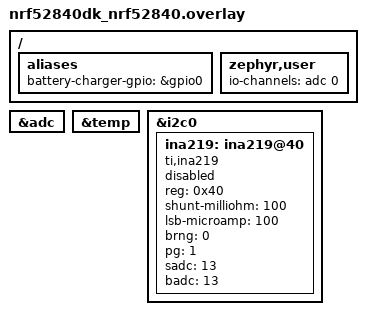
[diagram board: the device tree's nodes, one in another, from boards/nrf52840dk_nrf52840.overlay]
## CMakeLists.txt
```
cmake_minimum_required(VERSION 3.20.0)
find_package(Zephyr REQUIRED HINTS $ENV{ZEPHYR_BASE})
project(battery_sdk_app)

target_sources(app PRIVATE
    src/main.c
    ../src/core/battery_sdk.c
    ../src/core_modules/battery_adc.c
    ../src/core_modules/battery_power_manager.c
    ../src/core_modules/battery_temperature.c
    ../src/core_modules/battery_voltage.c
    ../src/intelligence/battery_soc_estimator.c
    ../src/intelligence/battery_soc_lut.c
    $<$<BOOL:${CONFIG_BATTERY_SOC_TEMP_COMP}>:../src/intelligence/battery_soc_temp_comp.c>
    ../src/telemetry/battery_telemetry.c
    $<$<BOOL:${CONFIG_BATTERY_TRANSPORT}>:../src/transport/battery_transport.c>
    $<$<BOOL:${CONFIG_BATTERY_TRANSPORT}>:../src/transport/battery_serialize.c>
    $<$<BOOL:${CONFIG_BATTERY_TRANSPORT_BLE}>:../src/transport/ble/battery_transport_ble_zephyr.c>
    ../src/hal/battery_hal_zephyr.c
    ../src/hal/battery_hal_adc_zephyr.c
    $<$<BOOL:${CONFIG_BATTERY_CHARGER_TP4056}>:../src/hal/battery_hal_charger_tp4056_zephyr.c>
    ../src/intelligence/battery_cycle_counter.c
)

# NVS HAL: real Zephyr NVS or stub
if(CONFIG_BATTERY_CYCLE_COUNTER OR CONFIG_BATTERY_SOC_SOH)
    target_sources(app PRIVATE ../src/hal/battery_hal_nvs_zephyr.c)
else()
    target_sources(app PRIVATE ../src/hal/battery_hal_nvs_stub.c)
endif()

# Current sensing HAL: Zephyr sensor API or stub
if(CONFIG_BATTERY_CURRENT_SENSE)
    target_sources(app PRIVATE ../src/hal/battery_hal_current_zephyr.c)
else()
    target_sources(app PRIVATE ../src/hal/battery_hal_current_stub.c)
endif()

# Coulomb counter
if(CONFIG_BATTERY_SOC_COULOMB)
    target_sources(app PRIVATE ../src/intelligence/battery_coulomb.c)
endif()

# SoC fusion (voltage + coulomb blending)
if(CONFIG_BATTERY_SOC_FUSION)
    target_sources(app PRIVATE ../src/intelligence/battery_soc_fusion.c)
endif()

# Runtime-to-empty estimator (time remaining)
if(CONFIG_BATTERY_RUNTIME_TO_EMPTY)
    target_sources(app PRIVATE ../src/intelligence/battery_runtime.c)
endif()

# State of Health (capacity-fade learning)
if(CONFIG_BATTERY_SOC_SOH)
    target_sources(app PRIVATE ../src/intelligence/battery_soh.c)
endif()

# Swap-aware SoH auto-reset (power-off battery swap detection)
if(CONFIG_BATTERY_SWAP_DETECT)
    target_sources(app PRIVATE ../src/intelligence/battery_swap.c)
endif()

# Zephyr fuel_gauge driver API (read-only) + its conversion helpers
if(CONFIG_BATTERY_FUEL_GAUGE_API)
    target_sources(app PRIVATE
        ../src/fuel_gauge/battery_fuel_gauge_zephyr.c
        ../src/core_modules/battery_fuel_gauge_convert.c
    )
endif()

# Voltage filter: moving-average (default) or median
if(CONFIG_BATTERY_VOLTAGE_FILTER_MEDIAN)
    target_sources(app PRIVATE ../src/core_modules/battery_voltage_filter_median.c)
else()
    target_sources(app PRIVATE ../src/core_modules/battery_voltage_filter.c)
endif()

# Temperature HAL: NTC thermistor or internal die sensor
if(CONFIG_BATTERY_TEMP_NTC)
    target_sources(app PRIVATE
        ../src/hal/battery_hal_temp_ntc_zephyr.c
        ../src/intelligence/battery_ntc_lut.c
    )
else()
    target_sources(app PRIVATE
        ../src/hal/battery_hal_temp_zephyr.c
    )
endif()

target_include_directories(app PRIVATE
    ${CMAKE_CURRENT_SOURCE_DIR}/../include
    ${CMAKE_CURRENT_SOURCE_DIR}/../src
    ${CMAKE_CURRENT_SOURCE_DIR}/../src/core
    ${CMAKE_CURRENT_SOURCE_DIR}/../src/core_modules
    ${CMAKE_CURRENT_SOURCE_DIR}/../src/hal
    ${CMAKE_CURRENT_SOURCE_DIR}/../src/intelligence
    ${CMAKE_CURRENT_SOURCE_DIR}/../src/telemetry
    ${CMAKE_CURRENT_SOURCE_DIR}/../src/transport
)
```

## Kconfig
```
# Battery SDK sample-application configuration.
#
# All CONFIG_BATTERY_* option definitions live in app/Kconfig.battery, which
# is ALSO sourced by the Zephyr-module Kconfig (Kconfig.ibattery) — single
# source of truth, so the app and module config trees cannot drift.

rsource "Kconfig.battery"

source "Kconfig.zephyr"
```

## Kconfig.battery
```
# iBattery SDK — battery option definitions (single source of truth)
#
# Sourced by BOTH the sample-app Kconfig (app/Kconfig) and the Zephyr-module
# Kconfig (Kconfig.ibattery), so the app and module config trees cannot drift.
# Define every CONFIG_BATTERY_* option here — nowhere else.

menu "Battery SDK"

choice BATTERY_CHEMISTRY
    prompt "Battery chemistry"
    default BATTERY_CHEMISTRY_CR2032

config BATTERY_CHEMISTRY_CR2032
    bool "CR2032 primary lithium coin cell (3.0 V nominal)"
    help
      CR2032 primary (non-rechargeable) lithium coin cell.
      Nominal voltage 3.0 V, cutoff ~2.0 V.

config BATTERY_CHEMISTRY_LIPO
    bool "LiPo single-cell (3.7 V nominal)"
    help
      Lithium-polymer rechargeable cell.  Nominal voltage 3.7 V,
      full charge 4.2 V, cutoff 3.0 V.

endchoice

choice BATTERY_TEMP_SOURCE
    prompt "Temperature sensor source"
    default BATTERY_TEMP_NTC

config BATTERY_TEMP_NTC
    bool "External NTC thermistor (10K B3950)"
    help
      Use an external NTC thermistor in a voltage divider on an ADC
      channel for temperature measurement. The exact pin is defined in
      the board's devicetree overlay. Requires a 10K pull-up resistor
      to VDD and a 10K NTC (B=3950) to GND.

config BATTERY_TEMP_DIE
    bool "Internal die temperature sensor"
    select SENSOR
    select TEMP_NRF5 if SOC_SERIES_NRF52X
    select ESP32_TEMP if SOC_SERIES_ESP32C3
    help
      Use the SoC internal die temperature sensor via the Zephyr
      sensor API. No external components needed, but measures chip
      temperature rather than ambient/battery temperature.

endchoice

choice BATTERY_VOLTAGE_FILTER_TYPE
    prompt "Voltage filter algorithm"
    default BATTERY_VOLTAGE_FILTER_MEAN

config BATTERY_VOLTAGE_FILTER_MEAN
    bool "Moving average (legacy)"
    help
      Simple moving average over the configured window. Smooths
      gradual changes but lets short voltage sags through.

config BATTERY_VOLTAGE_FILTER_MEDIAN
    bool "Median (rejects load-induced sags)"
    help
      Sorted median over the configured window. Single-sample
      outliers (e.g. BLE TX voltage sag) are completely rejected.

endchoice

config BATTERY_TRANSPORT
    bool "Enable telemetry transport"
    default n
    help
      Enable the transport abstraction layer for sending telemetry
      packets off-device (BLE, serial, etc.).

if BATTERY_TRANSPORT

choice BATTERY_TRANSPORT_BACKEND
    prompt "Transport backend"
    default BATTERY_TRANSPORT_BLE

config BATTERY_TRANSPORT_BLE
    bool "Bluetooth Low Energy (BLE)"
    select BT
    select BT_PERIPHERAL
    help
      Send telemetry via BLE GATT notifications using a custom service.
      Requires a BLE-capable SoC or external BLE shield (e.g.
      X-NUCLEO-IDB05A2 on STM32 Nucleo boards).

endchoice

endif # BATTERY_TRANSPORT

config BATTERY_SOC_TEMP_COMP
    bool "Temperature-compensated SoC estimation"
    default y if BATTERY_TEMP_NTC && BATTERY_CHEMISTRY_LIPO
    depends on BATTERY_CHEMISTRY_LIPO
    help
      Enable temperature-compensated SoC estimation by blending between
      cold (0 deg C), room (25 deg C), and hot (45 deg C) LiPo LUT tables.
      Requires LiPo chemistry and a working temperature sensor.  Falls back
      to room-temperature LUT if the temperature read fails at runtime.

config BATTERY_CYCLE_COUNTER
    bool "Charge cycle counter with flash persistence"
    default y if BATTERY_CHARGER_TP4056
    select NVS
    select FLASH
    select FLASH_MAP
    help
      Count CHARGING to CHARGED transitions and persist the count
      to flash via Zephyr NVS.  Requires a charger driver for meaningful
      state transitions.

config BATTERY_CURRENT_SENSE
    bool "Enable current sensing (INA219)"
    default n
    select SENSOR
    select I2C
    help
      Enable current measurement via an INA219 I2C sensor.
      Required for coulomb counting SoC estimation.
      The INA219 must be defined in the board's devicetree overlay.

config BATTERY_VOLTAGE_ADC
    bool
    default y
    select ADC
    help
      The Zephyr voltage HAL (src/hal/battery_hal_adc_zephyr.c) is compiled
      unconditionally and hard-depends on the ADC subsystem (DEVICE_DT_GET of
      the ADC node + adc_raw_to_millivolts/adc_gain_invert).  Pull ADC in here
      so the SDK declares its own dependency — mirroring how BATTERY_TEMP_DIE
      selects SENSOR.  Without this, a module consumer that does not set
      CONFIG_ADC itself fails to link (the sample app sets CONFIG_ADC=y in its
      prj.conf, which masked this on the app-path build).  Hidden / always-on.

config BATTERY_VOLTAGE_EXTERNAL_ADC
    bool "Read battery voltage from an external ADC pin + resistor divider"
    default n
    help
      Read battery voltage from an external resistor divider on an ADC pin
      instead of the internal VDD path (STM32 VREFINT).  This lets a real
      cell or a bench source-measure unit (e.g. Nordic PPK2) drive the sensed
      voltage independently of the MCU supply, so a full->empty excursion can
      be exercised without browning out the board.  STM32L4 reads Arduino A2 /
      PA4 (ADC1_IN9); the board overlay must enable that channel.  ESP32-C3
      always uses an external divider regardless of this option.

config BATTERY_VOLTAGE_DIVIDER_RATIO
    int "Battery voltage divider ratio (R1+R2)/R2"
    default 2
    range 1 16
    depends on BATTERY_VOLTAGE_EXTERNAL_ADC
    help
      Ratio applied to the ADC pin voltage to reconstruct battery voltage.
      For R1 = R2 (e.g. 100k/100k) the ratio is 2 (V_batt = V_pin * 2).

config BATTERY_SOC_COULOMB
    bool "Coulomb counting SoC estimation"
    default y if BATTERY_CURRENT_SENSE
    depends on BATTERY_CURRENT_SENSE
    help
      Use coulomb counting (current integration) as the primary
      SoC estimation method, with voltage-LUT anchoring at
      full-charge and cutoff endpoints. Falls back to voltage-LUT
      if current sensor is unavailable at runtime.

config BATTERY_CAPACITY_MAH
    int "Battery capacity in mAh"
    range 1 65535
    default 220 if BATTERY_CHEMISTRY_CR2032
    default 1000 if BATTERY_CHEMISTRY_LIPO
    depends on BATTERY_SOC_COULOMB || BATTERY_FUEL_GAUGE_API
    help
      Nominal battery capacity in milliamp-hours. Used by the
      coulomb counting estimator to convert accumulated charge
      to SoC percentage.

config BATTERY_SOC_SLEW_LIMIT
    bool "Limit SoC change rate (smooths reported value)"
    default y
    help
      Caps the SoC change rate to a configurable maximum percent per
      minute. Filters transient SoC swings from voltage sag or LUT
      plateau cliffs. Bypassed on first sample after init.

config BATTERY_SOC_SLEW_RATE_PCT_PER_MIN
    int "Max SoC change per minute (percent)"
    default 5
    range 1 100
    depends on BATTERY_SOC_SLEW_LIMIT
    help
      Maximum allowed SoC change per minute.

config BATTERY_SOC_FUSION
    bool "Voltage + coulomb signal fusion"
    default n
    depends on BATTERY_SOC_COULOMB
    help
      Continuously fuses voltage-LUT SoC with coulomb-counter SoC to
      correct mid-discharge drift in the coulomb integrator. Trust
      shifts toward voltage when the battery is at rest (current below
      threshold) and toward coulomb under load (voltage sag is real).

      Composes with the endpoint anchor calibration (which still fires
      at the discharge curve's endpoints) and the SoC slew limiter (which
      still applies after fusion).

      Defaults to off. Enable per build to opt in.

if BATTERY_SOC_FUSION

config BATTERY_SOC_FUSION_ALPHA_REST_X1000
    int "Fusion alpha (x1000) when battery is at rest"
    default 50 if !BATTERY_CHEMISTRY_LIPO
    default 30 if BATTERY_CHEMISTRY_LIPO
    range 0 1000
    help
      Per-sample pull toward voltage-LUT SoC when the current magnitude
      is below the rest/load threshold (I_THRESH_X100).
      Larger = faster drift correction. Default 5.0% per sample (CR2032)
      gives ~95% convergence in ~60 samples at 2s intervals.
      LiPo default is 3.0% (LUT is flatter in the middle plateau, so
      voltage is less informative even at rest).

config BATTERY_SOC_FUSION_ALPHA_LOAD_X1000
    int "Fusion alpha (x1000) under load"
    default 5
    range 0 1000
    help
      Per-sample pull toward voltage-LUT SoC when the current magnitude
      is at or above the rest/load threshold (I_THRESH_X100).
      Should be small -- voltage is unreliable under load (IR drop).
      Default 0.5% per sample, both chemistries.

config BATTERY_SOC_FUSION_I_THRESH_X100
    int "Current threshold (x100 mA) classifying rest vs load"
    default 200 if !BATTERY_CHEMISTRY_LIPO
    default 5000 if BATTERY_CHEMISTRY_LIPO
    # Upper bound 500000 = 5000.00 mA (5 A) — generous even for a 500 mAh
    # LiPo (10C); defaults are 2 mA (CR2032) / 50 mA (LiPo).
    range 0 500000
    help
      Below this current magnitude, fusion uses ALPHA_REST.
      At or above it, uses ALPHA_LOAD. Units are x100 mA
      (e.g. 200 = 2.00 mA).

endif # BATTERY_SOC_FUSION

config BATTERY_SOC_SOH
    bool "State-of-Health (capacity-fade learning)"
    default n
    depends on BATTERY_SOC_COULOMB
    select NVS
    select FLASH
    select FLASH_MAP
    help
      Learns the battery's true usable capacity from full->empty discharge
      excursions and exposes State of Health (SoH = learned / rated). The
      coulomb integral between a full and an empty anchor is the actual
      delivered charge; an aged cell delivers less, which shows up as SoH
      below 100%. Learned capacity persists to flash (NVS) and is restored on
      boot behind a rated-capacity guard. Opt-in; default off.

if BATTERY_SOC_SOH

config BATTERY_SOC_SOH_ALPHA_X1000
    int "SoH EMA blend per valid excursion (x1000)"
    default 500
    range 0 1000
    help
      Per-excursion pull of learned capacity toward the freshly measured
      value. 500 = 50% (converges in a few cycles); smaller is steadier.

config BATTERY_SOC_SOH_REJECT_LO_PCT
    int "Reject measured capacity below this % of rated"
    default 30
    range 0 100
    help
      Plausibility floor for a full->empty excursion. A learned
      capacity below this percent of rated is treated as a bad
      measurement (e.g. a partial/aborted excursion) and discarded
      rather than fed into the SoH estimate.

config BATTERY_SOC_SOH_REJECT_HI_PCT
    int "Reject measured capacity above this % of rated"
    default 120
    range 100 200
    help
      Plausibility ceiling for a full->empty excursion. A learned
      capacity above this percent of rated is treated as implausible
      (e.g. current-sense error or over-anchored) and discarded.

endif # BATTERY_SOC_SOH

config BATTERY_SWAP_DETECT
    bool "Auto-detect a power-off battery swap and reset learned SoH"
    depends on BATTERY_SOC_SOH
    default y if BATTERY_CHEMISTRY_CR2032
    default n
    help
      On boot, if SoC jumped up vs the last persisted value, treat it as a
      swapped cell: reset learned SoH to rated and set the BATTERY_SWAPPED
      status flag. Primary-cell only — a rechargeable charged while powered
      off would look identical, so leave this OFF for LiPo until charge-vs-swap
      disambiguation (Phase 2) lands.

config BATTERY_SWAP_SOC_THRESHOLD_PCT_X100
    int "Swap detection: upward SoC jump that counts as a swap (0.01%)"
    default 2500
    range 100 10000
    depends on BATTERY_SWAP_DETECT

config BATTERY_SWAP_PERSIST_DELTA_PCT_X100
    int "Swap detection: SoC drop that triggers a baseline persist (0.01%)"
    default 500
    range 100 10000
    depends on BATTERY_SWAP_DETECT

config BATTERY_RUNTIME_TO_EMPTY
    bool "Estimate runtime-to-empty (minutes) from charge + smoothed current"
    default n
    depends on BATTERY_SOC_COULOMB
    help
      Estimate minutes until the battery is empty (remaining charge / smoothed
      discharge current). Adds wire format v5 and the Zephyr fuel_gauge
      RUNTIME_TO_EMPTY property. No effect when disabled.

config BATTERY_RUNTIME_EMA_ALPHA_X1000
    int "Runtime current EMA factor (x1000)"
    default 300
    range 1 1000
    depends on BATTERY_RUNTIME_TO_EMPTY

config BATTERY_RUNTIME_IDLE_THRESHOLD_MA_X100
    int "Idle current threshold (0.01 mA); at/below this -> not discharging"
    default 50
    range 0 100000
    depends on BATTERY_RUNTIME_TO_EMPTY
    help
      A smoothed discharge current at or below this is treated as idle and
      runtime-to-empty reports "not available". The 0.50 mA default sits above
      typical current-sense noise, so it both suppresses meaningless estimates
      from noise and bounds the largest estimate to (remaining charge / floor),
      preventing a multi-year spike while the EMA settles to zero after a load
      is removed. Set to 0 to report for any positive drain (legacy behavior).

config BATTERY_FUEL_GAUGE_API
    bool "Expose iBattery via the Zephyr fuel_gauge driver API (read-only)"
    default n
    select FUEL_GAUGE
    help
      Build a read-only Zephyr fuel_gauge driver that maps iBattery's outputs
      (SoC, voltage, current, capacity, cycle count, temperature) to the standard
      fuel_gauge properties, plus a custom State-of-Health property. Instantiated
      from a devicetree node with compatible "aliaksandr,ibattery-fuel-gauge".
      No effect when disabled.

config BATTERY_FUEL_GAUGE_SELFCHECK
    bool "Print fuel_gauge driver readings on serial (runtime validation aid)"
    default n
    depends on BATTERY_FUEL_GAUGE_API
    help
      Sample-app diagnostic: each telemetry cycle, read every property back
      through the standard fuel_gauge_get_prop() API and print it on serial
      next to the native telemetry line, so the driver's values and unit
      conversions can be eyeballed against the SDK's own output on hardware.
      Validation-only; leave off for normal builds.

config BATTERY_CHARGER_TP4056
    bool "TP4056 charger IC GPIO status detection"
    default n
    select GPIO
    help
      Enable detection of charging state via TP4056 CHRG and STDBY
      GPIO pins.  CHRG (active low) indicates charging in progress.
      STDBY (active low) indicates charge complete.

if BATTERY_CHARGER_TP4056

config BATTERY_CHARGER_TP4056_CHRG_PIN
    int "TP4056 CHRG GPIO pin number"
    default 28
    help
      GPIO pin connected to TP4056 CHRG output (P0.28 by default).
      Active low: LOW = charging, HIGH = not charging.

config BATTERY_CHARGER_TP4056_STDBY_PIN
    int "TP4056 STDBY GPIO pin number"
    default 29
    help
      GPIO pin connected to TP4056 STDBY output (P0.29 by default).
      Active low: LOW = charge complete, HIGH = not complete.

endif # BATTERY_CHARGER_TP4056

endmenu
```

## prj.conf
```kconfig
CONFIG_MAIN_STACK_SIZE=4096
CONFIG_LOG=y
CONFIG_LOG_DEFAULT_LEVEL=3
CONFIG_STDOUT_CONSOLE=y
CONFIG_PRINTK=y

CONFIG_ADC=y
CONFIG_CONSOLE=y
CONFIG_UART_CONSOLE=y

# Battery chemistry: CR2032 (default) or LIPO
# Switch to CONFIG_BATTERY_CHEMISTRY_LIPO=y for LiPo cells
CONFIG_BATTERY_CHEMISTRY_CR2032=y

# Temperature source: NTC thermistor (default) or die sensor
# Switch to CONFIG_BATTERY_TEMP_DIE=y to use the internal die sensor
CONFIG_BATTERY_TEMP_NTC=y

# ── BLE Telemetry Transport ──────────────────────────────────────────
CONFIG_BATTERY_TRANSPORT=y
CONFIG_BATTERY_TRANSPORT_BLE=y
CONFIG_BT=y
CONFIG_BT_PERIPHERAL=y
CONFIG_BT_DEVICE_NAME="iBattery"
CONFIG_SYSTEM_WORKQUEUE_STACK_SIZE=2048
CONFIG_BT_MAX_CONN=1
CONFIG_BT_MAX_PAIRED=1
# v5 telemetry is 38 bytes; a notification needs ATT_MTU >= 38 + 3 (ATT header).
# 27 silently capped payloads at 24 bytes, so v3+ packets never made it over BLE.
CONFIG_BT_L2CAP_TX_MTU=41
CONFIG_BT_BUF_ACL_TX_SIZE=45
CONFIG_BT_BUF_ACL_RX_SIZE=45
```

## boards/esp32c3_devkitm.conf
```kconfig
# Board-specific Kconfig for ESP32-C3 DevKitM
# Auto-loaded by Zephyr build system (app/boards/<board>.conf)

CONFIG_ADC=y
CONFIG_SENSOR=y

# Use die temperature sensor by default — most accurate on ESP32-C3.
# Switch to CONFIG_BATTERY_TEMP_NTC=y for external NTC on GPIO3
# (requires 10K NTC + 10K pullup; ESP32 ADC may need calibration tuning).
CONFIG_BATTERY_TEMP_DIE=y

# LiPo chemistry for voltage divider validation
CONFIG_BATTERY_CHEMISTRY_LIPO=y

# ESP32-C3 has native BLE — enable transport by default.
CONFIG_BATTERY_TRANSPORT=y
CONFIG_BATTERY_TRANSPORT_BLE=y
CONFIG_BT=y
CONFIG_BT_PERIPHERAL=y
CONFIG_BT_DEVICE_NAME="iBattery-ESP32C3"
CONFIG_SYSTEM_WORKQUEUE_STACK_SIZE=2048
CONFIG_BT_MAX_CONN=1
CONFIG_BT_MAX_PAIRED=1
# v5 telemetry is 38 bytes; a notification needs ATT_MTU >= 38 + 3 (ATT header).
# 27 silently capped payloads at 24 bytes, so v3+ packets never made it over BLE.
CONFIG_BT_L2CAP_TX_MTU=41
CONFIG_BT_BUF_ACL_TX_SIZE=45
CONFIG_BT_BUF_ACL_RX_SIZE=45

# TP4056 charger: disabled by default. Enable CONFIG_BATTERY_CHARGER_TP4056=y
# and set pin numbers when TP4056 hardware is wired.
# CONFIG_BATTERY_CHARGER_TP4056_CHRG_PIN=6
# CONFIG_BATTERY_CHARGER_TP4056_STDBY_PIN=7

# ── Current Sensing (INA219) ────────────────────────────────────────
# Uncomment to enable coulomb counting with INA219
# CONFIG_BATTERY_CURRENT_SENSE=y
# CONFIG_BATTERY_SOC_COULOMB=y
# CONFIG_BATTERY_CAPACITY_MAH=1000
# CONFIG_I2C=y
```

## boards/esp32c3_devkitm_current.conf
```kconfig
# Current sensing with INA219
CONFIG_I2C=y
CONFIG_BATTERY_CURRENT_SENSE=y
CONFIG_BATTERY_SOC_COULOMB=y
CONFIG_BATTERY_CAPACITY_MAH=1000
```

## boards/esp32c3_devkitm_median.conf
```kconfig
# Median voltage filter (alternative to default moving-average)
CONFIG_BATTERY_VOLTAGE_FILTER_MEDIAN=y
```

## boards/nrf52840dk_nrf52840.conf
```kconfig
# Auto-merged for board nrf52840dk/nrf52840 (Zephyr applies boards/<board>.conf
# automatically, like the sibling nrf52840dk_nrf52840.overlay).
#
# Give the nRF52840-DK a board-specific BLE name so the gateway/Grafana "device"
# tag distinguishes it from the STM32 ("iBattery-STM32") and ESP32-C3
# ("iBattery-ESP32C3") builds. Without this the nRF falls back to prj.conf's
# generic "iBattery".
CONFIG_BT_DEVICE_NAME="iBattery-nRF52840"
```

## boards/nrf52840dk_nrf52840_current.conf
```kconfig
# Current sensing with INA219 on nRF52840-DK
CONFIG_I2C=y
CONFIG_BATTERY_CURRENT_SENSE=y
CONFIG_BATTERY_SOC_COULOMB=y
CONFIG_BATTERY_CAPACITY_MAH=220
```

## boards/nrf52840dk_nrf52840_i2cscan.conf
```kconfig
# Minimal I2C scan config — just to test if INA219 is on the bus
CONFIG_I2C=y
CONFIG_SHELL=y
CONFIG_I2C_SHELL=y
CONFIG_BATTERY_CURRENT_SENSE=y
CONFIG_BATTERY_SOC_COULOMB=y
CONFIG_BATTERY_CAPACITY_MAH=220
```

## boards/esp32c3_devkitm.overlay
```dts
/*
 * Device tree overlay for Battery SDK on ESP32-C3 DevKitM.
 *
 * ADC0:  channel 2 = GPIO2 (battery voltage via external divider)
 *        channel 3 = GPIO3 (external NTC thermistor)
 * GPIO:  GPIO6 = TP4056 CHRG, GPIO7 = TP4056 STDBY
 *
 * Battery voltage divider circuit:
 *   Battery+ --- [100K R1] ---+--- [100K R2] --- GND
 *                             |
 *                           GPIO2 (ADC1 ch2)
 *
 *   V_adc = V_batt * R2 / (R1 + R2) = V_batt / 2
 *   Firmware multiplies ADC reading by 2 to get battery voltage.
 */

/ {
	aliases {
		battery-charger-gpio = &gpio0;
	};
};

&adc0 {
	status = "okay";
};

/* Enable die temperature sensor */
&coretemp {
	status = "okay";
};

/* INA219 current sensor on I2C0 (SDA=GPIO1, SCL=GPIO3).
 * Status "disabled" prevents Zephyr driver from running at boot
 * (which corrupts the I2C bus on ESP32-C3). The SDK HAL uses raw I2C. */
&i2c0 {
	ina219: ina219@40 {
		compatible = "ti,ina219";
		reg = <0x40>;
		status = "disabled";
		shunt-milliohm = <100>;
		lsb-microamp = <100>;
		brng = <0>;
		pg = <1>;
		sadc = <13>;
		badc = <13>;
	};
};
```

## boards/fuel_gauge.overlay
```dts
/ {
    ibattery_fg: ibattery_fuel_gauge {
        compatible = "aliaksandr,ibattery-fuel-gauge";
        status = "okay";
    };
};
```

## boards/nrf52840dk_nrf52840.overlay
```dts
/*
 * ADC overlay for Battery SDK.
 *
 * The HAL configures the SAADC channel directly via adc_channel_setup()
 * using NRFX_ANALOG_INTERNAL_VDD (internal VDD rail measurement).
 * The zephyr,user io-channels node is retained as a placeholder for
 * future external ADC channels (e.g., NTC thermistor in Phase 2).
 */
/ {
    aliases {
        battery-charger-gpio = &gpio0;
    };

    zephyr,user {
        io-channels = <&adc 0>;
    };
};

&adc {
    status = "okay";
};

&temp {
    status = "okay";
};

/* INA219 current sensor on I2C0 (SDA=P0.26, SCL=P0.27 — Arduino header) */
&i2c0 {
    ina219: ina219@40 {
        compatible = "ti,ina219";
        reg = <0x40>;
        status = "disabled";
        shunt-milliohm = <100>;
        lsb-microamp = <100>;
        brng = <0>;
        pg = <1>;
        sadc = <13>;
        badc = <13>;
    };
};
```

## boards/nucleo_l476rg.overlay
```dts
/*
 * Device tree overlay for Battery SDK on NUCLEO-L476RG.
 *
 * ADC1:  channel 0 = VREFINT (internal, for VDD measurement)
 *        channel 5 = PA0 / Arduino A0 (external NTC thermistor)
 * GPIO:  PC6 = TP4056 CHRG, PC7 = TP4056 STDBY
 */

/ {
	aliases {
		battery-charger-gpio = &gpioc;
	};
};

&adc1 {
	status = "okay";
};

/* Enable VREFINT sensor for VDD measurement */
&vref {
	status = "okay";
};

/* Enable die temperature sensor for CONFIG_BATTERY_TEMP_DIE option */
&die_temp {
	status = "okay";
};

/* INA219 current sensor on I2C1 (SCL=PB8 / D15, SDA=PB9 / D14 — Arduino header) */
&i2c1 {
	ina219: ina219@40 {
		compatible = "ti,ina219";
		reg = <0x40>;
		status = "disabled";
		shunt-milliohm = <100>;
		lsb-microamp = <100>;
		brng = <0>;
		pg = <1>;
		sadc = <13>;
		badc = <13>;
	};
};
```

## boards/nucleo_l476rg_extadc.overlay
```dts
/*
 * External-ADC battery-voltage sense for NUCLEO-L476RG.
 *
 * Adds ADC1 channel 9 on PA4 (Arduino A2) so battery voltage can be read from
 * an external resistor divider (see CONFIG_BATTERY_VOLTAGE_EXTERNAL_ADC).
 * A2/PA4 is used (not A1) because the X-NUCLEO-IDB05A1 BLE shield claims A0
 * (IRQ) and A1 (SPI CS).
 * Applied on top of the auto-included nucleo_l476rg.overlay via
 * -DEXTRA_DTC_OVERLAY_FILE=boards/nucleo_l476rg_extadc.overlay
 *
 * Wire the divider per docs/WIRING.md:
 *   V_sense(+) -> [100k] -> A2/PA4 -> [100k] -> GND   (+ 100 nF A2->GND)
 */

&adc1 {
	pinctrl-0 = <&adc1_in9_pa4>;
	pinctrl-names = "default";
	status = "okay";
};
```

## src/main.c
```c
#include <zephyr/kernel.h>
#include <zephyr/sys/printk.h>

#include <battery_sdk/battery_sdk.h>
#include <battery_sdk/battery_status.h>
#include <battery_sdk/battery_telemetry.h>

#if IS_ENABLED(CONFIG_BATTERY_TRANSPORT)
#include <battery_sdk/battery_transport.h>
#endif

#if IS_ENABLED(CONFIG_BATTERY_FUEL_GAUGE_SELFCHECK)
#include <zephyr/device.h>
#include <zephyr/drivers/fuel_gauge.h>
#include <battery_sdk/battery_fuel_gauge.h>
#endif

#include <stdint.h>

static void print_platform_info(void)
{
    printk("\n=== iBattery SDK — On-Target Validation ===\n");

#if defined(CONFIG_SOC_SERIES_STM32L4X)
    printk("Platform: STM32L4 (NUCLEO-L476RG)\n");
    printk("VDD read: VREFINT sensor\n");
#elif defined(CONFIG_SOC_SERIES_NRF52X)
    printk("Platform: nRF52 (nRF52840-DK)\n");
    printk("VDD read: SAADC direct\n");
#elif defined(CONFIG_SOC_SERIES_ESP32C3)
    printk("Platform: ESP32-C3 (DevKitM)\n");
    printk("VDD read: External voltage divider\n");
#else
    printk("Platform: unknown\n");
#endif

#if IS_ENABLED(CONFIG_BATTERY_TEMP_NTC)
    printk("Temp src: NTC thermistor (external)\n");
#elif IS_ENABLED(CONFIG_BATTERY_TEMP_DIE)
    printk("Temp src: Die sensor (internal)\n");
#endif

#if IS_ENABLED(CONFIG_BATTERY_CHEMISTRY_LIPO)
    printk("Chemistry: LiPo (3.7V)\n");
#else
    printk("Chemistry: CR2032 (3.0V)\n");
#endif

#if IS_ENABLED(CONFIG_BATTERY_TRANSPORT)
    printk("Transport: BLE enabled\n");
#else
    printk("Transport: disabled\n");
#endif

#if IS_ENABLED(CONFIG_BATTERY_CHARGER_TP4056)
    printk("Charger:   TP4056 GPIO\n");
#else
    printk("Charger:   disabled\n");
#endif

#if IS_ENABLED(CONFIG_BATTERY_CURRENT_SENSE)
    printk("Current:   INA219 (coulomb counting)\n");
#else
    printk("Current:   disabled\n");
#endif

    printk("============================================\n\n");
}

#if IS_ENABLED(CONFIG_BATTERY_FUEL_GAUGE_SELFCHECK)
/* Read each property back through the standard fuel_gauge API and print raw
 * values + units, so they can be compared against the native telemetry line.
 * Expected conversions: V uV = mV*1000; I uA = -(mA*1000) [neg=discharge];
 * T 0.1K = degC*10 + 2731(.5); SOC % = round(native SOC); REM/FULL uAh;
 * DESIGN mAh; CYC 1/100ths; SOH(flags) = native soh*100. set_prop = -ENOSYS. */
static void fuel_gauge_selfcheck(void)
{
    const struct device *fg = DEVICE_DT_GET_ANY(aliaksandr_ibattery_fuel_gauge);
    union fuel_gauge_prop_val v;

    if (fg == NULL || !device_is_ready(fg)) {
        printk("  [FG] device not ready\n");
        return;
    }

    printk("  [FG]");
    if (fuel_gauge_get_prop(fg, FUEL_GAUGE_VOLTAGE, &v) == 0) {
        printk(" V=%duV", v.voltage);
    }
    if (fuel_gauge_get_prop(fg, FUEL_GAUGE_CURRENT, &v) == 0) {
        printk(" I=%duA", v.current);
    }
    if (fuel_gauge_get_prop(fg, FUEL_GAUGE_AVG_CURRENT, &v) == 0) {
        printk(" AVGI=%duA", v.avg_current);
    }
    if (fuel_gauge_get_prop(fg, FUEL_GAUGE_TEMPERATURE, &v) == 0) {
        printk(" T=%u(0.1K)", v.temperature);
    }
    if (fuel_gauge_get_prop(fg, FUEL_GAUGE_RELATIVE_STATE_OF_CHARGE, &v) == 0) {
        printk(" SOC=%u%%", v.relative_state_of_charge);
    }
    if (fuel_gauge_get_prop(fg, FUEL_GAUGE_REMAINING_CAPACITY, &v) == 0) {
        printk(" REM=%uuAh", v.remaining_capacity);
    }
    if (fuel_gauge_get_prop(fg, FUEL_GAUGE_FULL_CHARGE_CAPACITY, &v) == 0) {
        printk(" FULL=%uuAh", v.full_charge_capacity);
    }
    if (fuel_gauge_get_prop(fg, FUEL_GAUGE_DESIGN_CAPACITY, &v) == 0) {
        printk(" DESIGN=%umAh", v.design_cap);
    }
    if (fuel_gauge_get_prop(fg, FUEL_GAUGE_CYCLE_COUNT, &v) == 0) {
        printk(" CYC=%u(1/100)", v.cycle_count);
    }
    if (fuel_gauge_get_prop(fg, BATTERY_FUEL_GAUGE_PROP_SOH, &v) == 0) {
        printk(" SOH(flags)=%u", v.flags);
    }
    /* read-only contract: set_property must report not-supported */
    printk(" set_rc=%d", fuel_gauge_set_prop(fg, FUEL_GAUGE_VOLTAGE, v));
    printk("\n");
}
#endif /* CONFIG_BATTERY_FUEL_GAUGE_SELFCHECK */

int main(void)
{
    struct battery_telemetry_packet pkt;
    int rc;

    print_platform_info();

    rc = battery_sdk_init();
    if (rc != BATTERY_STATUS_OK) {
        printk("Battery SDK init failed: %d\n", rc);
    } else {
        printk("Battery SDK initialized OK\n");
    }

    while (1) {
        rc = battery_telemetry_collect(&pkt);
        if (rc != BATTERY_STATUS_OK) {
            printk("Telemetry collect failed: %d\n", rc);
        } else {
            printk("[v%u t=%u] V=%d mV T=%d.%02d C SOC=%u.%02u%% PWR=%u CYC=%u flags=0x%08x",
                   pkt.telemetry_version,
                   pkt.timestamp_ms,
                   pkt.voltage_mv,
                   pkt.temperature_c_x100 / 100,
                   (pkt.temperature_c_x100 >= 0)
                       ? (pkt.temperature_c_x100 % 100)
                       : -(pkt.temperature_c_x100 % 100),
                   pkt.soc_pct_x100 / 100U,
                   pkt.soc_pct_x100 % 100U,
                   pkt.power_state,
                   pkt.cycle_count,
                   pkt.status_flags);

#if IS_ENABLED(CONFIG_BATTERY_CURRENT_SENSE)
            printk(" I=%d.%02d mA Q=%d.%02d mAh",
                   pkt.current_ma_x100 / 100,
                   (pkt.current_ma_x100 >= 0)
                       ? (pkt.current_ma_x100 % 100)
                       : -(pkt.current_ma_x100 % 100),
                   pkt.coulomb_mah_x100 / 100,
                   (pkt.coulomb_mah_x100 >= 0)
                       ? (pkt.coulomb_mah_x100 % 100)
                       : -(pkt.coulomb_mah_x100 % 100));
#endif
#if IS_ENABLED(CONFIG_BATTERY_SOC_SOH)
            printk(" SOH=%u.%02u%%",
                   pkt.soh_pct_x100 / 100U,
                   pkt.soh_pct_x100 % 100U);
#endif
#if IS_ENABLED(CONFIG_BATTERY_RUNTIME_TO_EMPTY)
            if (pkt.runtime_to_empty_min == UINT32_MAX) {
                printk(" RTE=n/a");
            } else {
                printk(" RTE=%u min", pkt.runtime_to_empty_min);
            }
#endif
            printk("\n");

#if IS_ENABLED(CONFIG_BATTERY_FUEL_GAUGE_SELFCHECK)
            fuel_gauge_selfcheck();
#endif

#if IS_ENABLED(CONFIG_BATTERY_TRANSPORT)
            rc = battery_transport_send(&pkt);
            if (rc != BATTERY_STATUS_OK) {
                printk("Transport send failed: %d\n", rc);
            }
#endif
        }

        k_sleep(K_SECONDS(2));
    }

    return 0;
}
```
